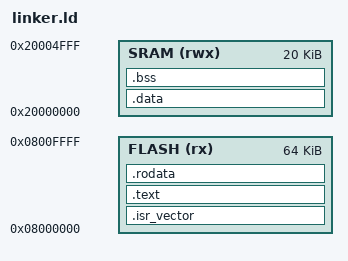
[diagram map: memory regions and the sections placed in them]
/* FLASH 64KB, RAM 20KB */


MEMORY 
{
    FLASH (rx)  : ORIGIN = 0x08000000, LENGTH = 64K
    SRAM  (rwx) : ORIGIN = 0x20000000, LENGTH = 20K
}

ENTRY(Reset_Handler)
_estack = ORIGIN(SRAM) + LENGTH(SRAM);

SECTIONS {
    .isr_vector :
    {
        . = ALIGN(4);
        KEEP(*(.isr_vector))
        . = ALIGN(4);
    } > FLASH

    .text :
    {
        . = ALIGN(4);
        *(.text)
        *(.text*)
        . = ALIGN(4);
        _etext = .;
    } > FLASH

    .rodata :
    {
        . = ALIGN(4);
        *(.rodata)
        *(.rodata*)
        . = ALIGN(4);
    } > FLASH
    
    .data : AT (ADDR(.text) + SIZEOF(.text) + SIZEOF(.rodata))
    {
        . = ALIGN(4);
        _sdata = .;
        *(.data)
        *(.data*)
        . = ALIGN(4);
        _edata = .;
    } > SRAM

    _sidata = LOADADDR(.data);

    .bss :
    {
        . = ALIGN(4);
        _sbss = .;
        __bss_start__ = _sbss;
        *(.bss)
        *(.bss*)
        *(COMMON)
        . = ALIGN(4);
        _ebss = .;
        __bss_end__ = _ebss;
    } > SRAM
}
